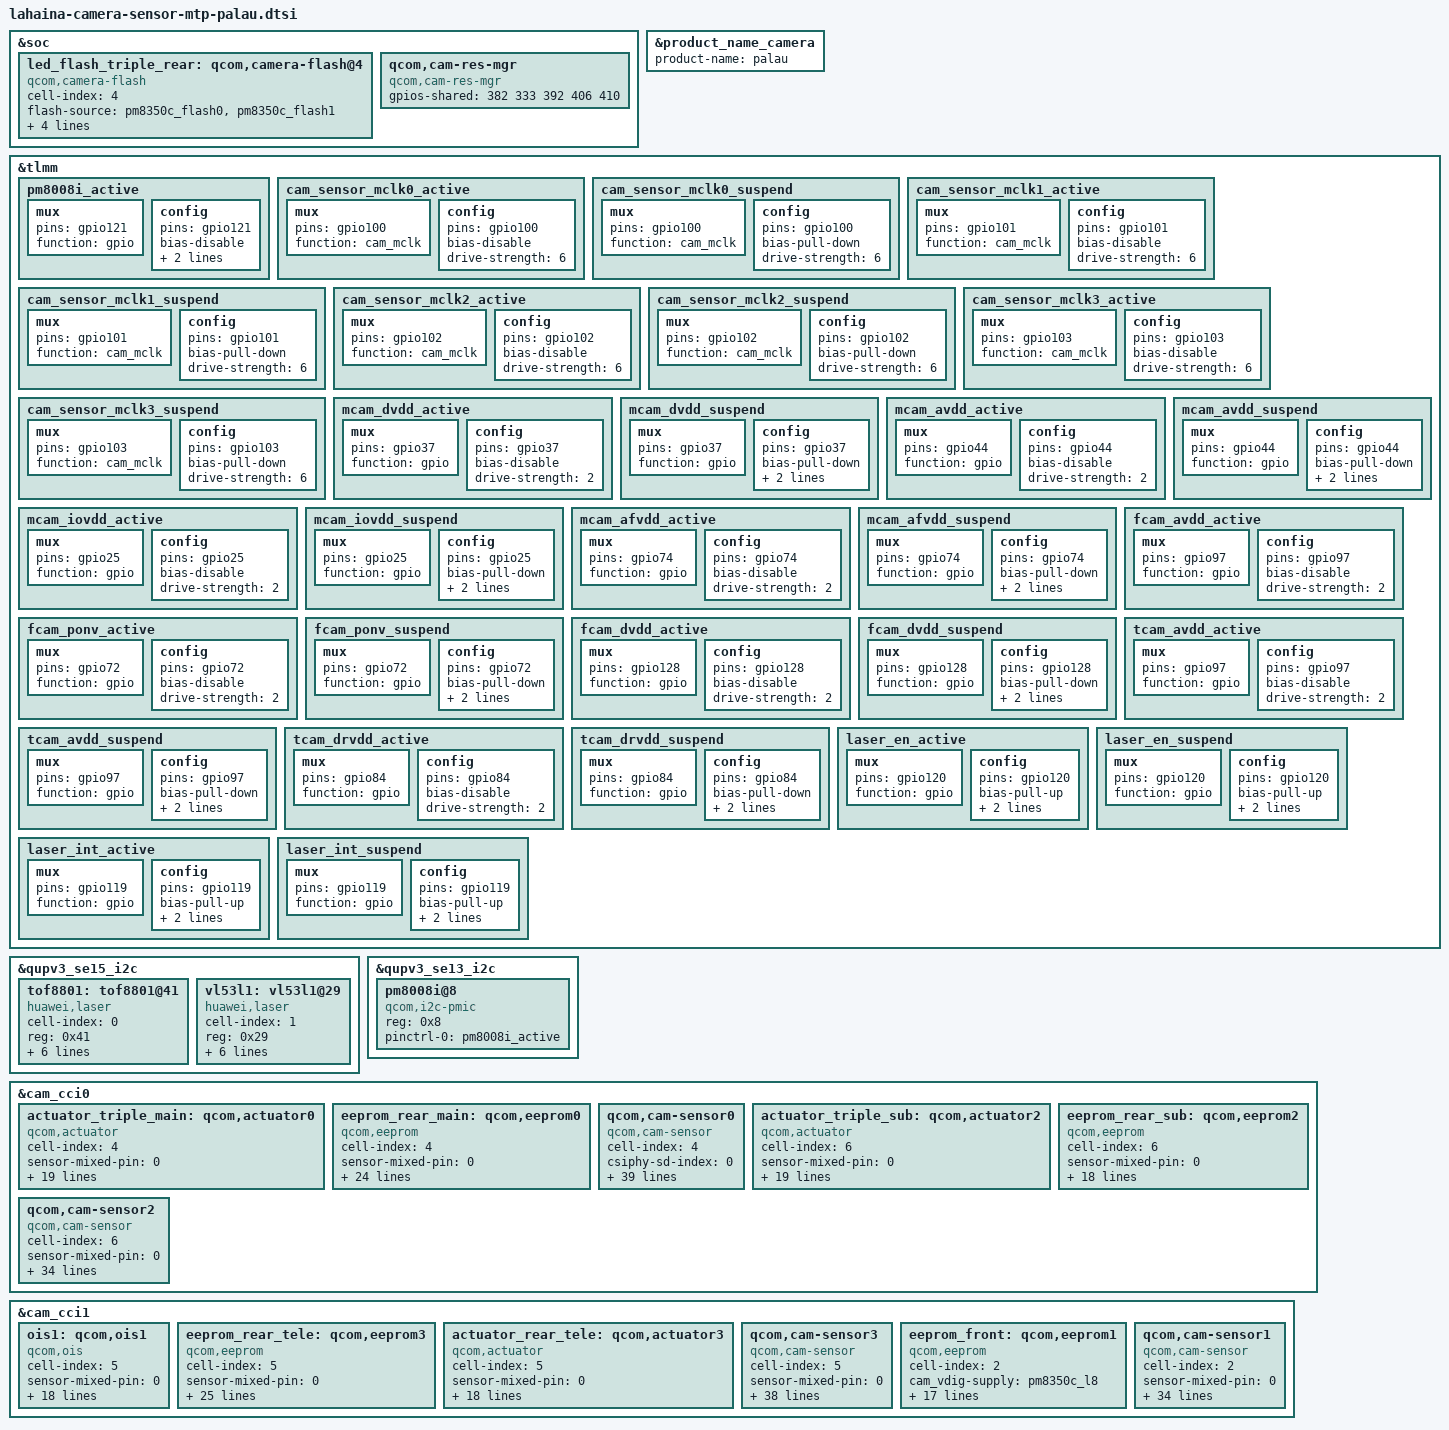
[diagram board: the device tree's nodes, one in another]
#include <dt-bindings/clock/qcom,camcc-lahaina.h>

&soc {
	led_flash_triple_rear: qcom,camera-flash@4 {
		cell-index = <4>;
		compatible = "qcom,camera-flash";
		flash-source = <&pm8350c_flash0 &pm8350c_flash1>;
		torch-source = <&pm8350c_torch0 &pm8350c_torch1>;
		switch-source = <&pm8350c_switch2>;
		torch-light-num = <0 1>;
		torch-light-name = "torch-light0", "torch-light1";
		status = "ok";
	};

	qcom,cam-res-mgr {
		compatible = "qcom,cam-res-mgr";
		status = "ok";
		gpios-shared = <382 333 392 406 410>;
	};
};

&product_name_camera {
    product-name = "palau";
};

&tlmm {
	pm8008i_active {
		mux {
			pins = "gpio121";
			function = "gpio";
		};

		config {
			pins = "gpio121";
			bias-disable;
			output-low;
			drive-strength = <2>;
		};
	};

	cam_sensor_mclk0_active: cam_sensor_mclk0_active {
		/* MCLK0 */
		mux {
			pins = "gpio100";
			function = "cam_mclk";
		};

		config {
			pins = "gpio100";
			bias-disable; /* No PULL */
			drive-strength = <6>; /* 6 MA */
		};
	};

	cam_sensor_mclk0_suspend: cam_sensor_mclk0_suspend {
		/* MCLK0 */
		mux {
			pins = "gpio100";
			function = "cam_mclk";
		};

		config {
			pins = "gpio100";
			bias-pull-down; /* PULL DOWN */
			drive-strength = <6>; /* 6 MA */
		};
	};

	cam_sensor_mclk1_active: cam_sensor_mclk1_active {
		/* MCLK1 */
		mux {
			pins = "gpio101";
			function = "cam_mclk";
		};

		config {
			pins = "gpio101";
			bias-disable; /* No PULL */
			drive-strength = <6>; /* 6 MA */
		};
	};

	cam_sensor_mclk1_suspend: cam_sensor_mclk1_suspend {
		/* MCLK1 */
		mux {
			pins = "gpio101";
			function = "cam_mclk";
		};

		config {
			pins = "gpio101";
			bias-pull-down; /* PULL DOWN */
			drive-strength = <6>; /* 6 MA */
		};
	};

	cam_sensor_mclk2_active: cam_sensor_mclk2_active {
		/* MCLK2 */
		mux {
			pins = "gpio102";
			function = "cam_mclk";
		};

		config {
			pins = "gpio102";
			bias-disable; /* No PULL */
			drive-strength = <6>; /* 6 MA */
		};
	};

	cam_sensor_mclk2_suspend: cam_sensor_mclk2_suspend {
		/* MCLK2 */
		mux {
			pins = "gpio102";
			function = "cam_mclk";
		};

		config {
			pins = "gpio102";
			bias-pull-down; /* PULL DOWN */
			drive-strength = <6>; /* 6 MA */
		};
	};

	cam_sensor_mclk3_active: cam_sensor_mclk3_active {
		/* MCLK3 */
		mux {
			pins = "gpio103";
			function = "cam_mclk";
		};

		config {
			pins = "gpio103";
			bias-disable; /* No PULL */
			drive-strength = <6>; /* 6 MA */
		};
	};

	cam_sensor_mclk3_suspend: cam_sensor_mclk3_suspend {
		/* MCLK3 */
		mux {
			pins = "gpio103";
			function = "cam_mclk";
		};

		config {
			pins = "gpio103";
			bias-pull-down; /* PULL DOWN */
			drive-strength = <6>; /* 6 MA */
		};
	};


	mcam_dvdd_active: mcam_dvdd_active {
		/* DVDD 0-for main */
		mux {
			pins = "gpio37";
			function = "gpio";
		};

		config {
			pins = "gpio37";
			bias-disable; /* No PULL */
			drive-strength = <2>; /* 2 MA */
		};
	};

	mcam_dvdd_suspend: mcam_dvdd_suspend {
		mux {
			pins = "gpio37";
			function = "gpio";
		};

		config {
			pins = "gpio37";
			bias-pull-down; /* PULL DOWN */
			drive-strength = <2>; /* 2 MA */
			output-low;
		};
	};

	mcam_avdd_active: mcam_avdd_active {
		mux {
			pins = "gpio44";
			function = "gpio";
		};

		config {
			pins = "gpio44";
			bias-disable; /* No PULL */
			drive-strength = <2>; /* 2 MA */
		};
	};

	mcam_avdd_suspend: mcam_avdd_suspend {
		mux {
			pins = "gpio44";
			function = "gpio";
		};

		config {
			pins = "gpio44";
			bias-pull-down; /* PULL DOWN */
			drive-strength = <2>; /* 2 MA */
			output-low;
		};
	};

	mcam_iovdd_active: mcam_iovdd_active {
		mux {
			pins = "gpio25";
			function = "gpio";
		};

		config {
			pins = "gpio25";
			bias-disable; /* No PULL */
			drive-strength = <2>; /* 2 MA */
		};
	};

	mcam_iovdd_suspend: mcam_iovdd_suspend {
		mux {
			pins = "gpio25";
			function = "gpio";
		};

		config {
			pins = "gpio25";
			bias-pull-down; /* PULL DOWN */
			drive-strength = <2>; /* 2 MA */
			output-low;
		};
	};

	mcam_afvdd_active: mcam_afvdd_active {
		mux {
			pins = "gpio74";
			function = "gpio";
		};

		config {
			pins = "gpio74";
			bias-disable; /* No PULL */
			drive-strength = <2>; /* 2 MA */
		};
	};

	mcam_afvdd_suspend: mcam_afvdd_suspend {
		mux {
			pins = "gpio74";
			function = "gpio";
		};

		config {
			pins = "gpio74";
			bias-pull-down; /* PULL DOWN */
			drive-strength = <2>; /* 2 MA */
			output-low;
		};
	};

	fcam_avdd_active: fcam_avdd_active {
		mux {
			pins = "gpio97";
			function = "gpio";
		};

		config {
			pins = "gpio97";
			bias-disable; /* No PULL */
			drive-strength = <2>; /* 2 MA */
		};
	};
	fcam_ponv_active: fcam_ponv_active {
		mux {
			pins = "gpio72";
			function = "gpio";
		};

		config {
			pins = "gpio72";
			bias-disable; /* No PULL */
			drive-strength = <2>; /* 2 MA */
		};
	};

	fcam_ponv_suspend: fcam_ponv_suspend {
		mux {
			pins = "gpio72";
			function = "gpio";
		};

		config {
			pins = "gpio72";
			bias-pull-down; /* PULL DOWN */
			drive-strength = <2>; /* 2 MA */
			output-low;
		};
	};

	fcam_dvdd_active: fcam_dvdd_active {
		mux {
			pins = "gpio128";
			function = "gpio";
		};

		config {
			pins = "gpio128";
			bias-disable; /* No PULL */
			drive-strength = <2>; /* 2 MA */
		};
	};

	fcam_dvdd_suspend: fcam_dvdd_suspend {
		mux {
			pins = "gpio128";
			function = "gpio";
		};

		config {
			pins = "gpio128";
			bias-pull-down; /* PULL DOWN */
			drive-strength = <2>; /* 2 MA */
			output-low;
		};
	};

	tcam_avdd_active: tcam_avdd_active {
		mux {
			pins = "gpio97";
			function = "gpio";
		};

		config {
			pins = "gpio97";
			bias-disable; /* No PULL */
			drive-strength = <2>; /* 2 MA */
		};
	};

	tcam_avdd_suspend: tcam_avdd_suspend {
		mux {
			pins = "gpio97";
			function = "gpio";
		};

		config {
			pins = "gpio97";
			bias-pull-down; /* PULL DOWN */
			drive-strength = <2>; /* 2 MA */
			output-low;
		};
	};

	tcam_drvdd_active: tcam_drvdd_active {
		mux {
			pins = "gpio84";
			function = "gpio";
		};

		config {
			pins = "gpio84";
			bias-disable; /* No PULL */
			drive-strength = <2>; /* 2 MA */
		};
	};

	tcam_drvdd_suspend: tcam_drvdd_suspend {
		mux {
			pins = "gpio84";
			function = "gpio";
		};

		config {
			pins = "gpio84";
			bias-pull-down; /* PULL DOWN */
			drive-strength = <2>; /* 2 MA */
			output-low;
		};
	};

	laser_en_active: laser_en_active {
		/* laser en pin */
		mux {
			pins = "gpio120";
			function = "gpio";
		};

		config {
			pins = "gpio120";
			bias-pull-up; /* PULL UP */
			drive-strength = <2>; /* 2 MA */
			input-enable;
		};
	};

	laser_en_suspend: laser_en_suspend {
		/* laser en pin */
		mux {
			pins = "gpio120";
			function = "gpio";
		};

		config {
			pins = "gpio120";
			bias-pull-up; /* PULL UP */
			drive-strength = <2>; /* 2 MA */
			input-enable;
		};
	};

	laser_int_active: laser_int_active {
		/* laser int pin */
		mux {
			pins = "gpio119";
			function = "gpio";
		};

		config {
			pins = "gpio119";
			bias-pull-up; /* PULL UP */
			drive-strength = <2>; /* 2 MA */
			input-enable;
		};
	};

	laser_int_suspend: laser_int_suspend {
		/* laser int pin */
		mux {
			pins = "gpio119";
			function = "gpio";
		};

		config {
			pins = "gpio119";
			bias-pull-up; /* PULL UP */
			drive-strength = <2>; /* 2 MA */
			input-enable;
		};
	};
};

/* laser */
&qupv3_se15_i2c {
	status = "ok";

	tof8801: tof8801@41 {
		cell-index = <0>;
		compatible = "huawei,laser";
		reg = <0x41>;
		gpios = <&tlmm 120 0>,
			<&tlmm 119 0>;
		pinctrl-names = "laser_int_active", "laser_en_active";
		pinctrl-0 = <&laser_int_active>;
		pinctrl-1 = <&laser_en_active>;
		gpio-req-tbl-num = <0>;
		gpio-req-tbl-flags = <0>;
		gpio-req-tbl-label = "CAM_VAF0";
		status = "ok";
	};
	vl53l1: vl53l1@29 {
		cell-index = <1>;
		compatible = "huawei,laser";
		reg = <0x29>;
		gpios = <&tlmm 120 0>,
			<&tlmm 119 0>;
		pinctrl-names = "laser_int_active", "laser_en_active";
		pinctrl-0 = <&laser_int_active>;
		pinctrl-1 = <&laser_en_active>;
		gpio-req-tbl-num = <0>;
		gpio-req-tbl-flags = <0>;
		gpio-req-tbl-label = "CAM_VAF0";
		status = "ok";
	};

};
&qupv3_se13_i2c {
	#address-cells = <1>;
	#size-cells = <0>;
	status = "ok";

	pm8008i@8 {
		compatible = "qcom,i2c-pmic";
		reg = <0x8>;
		#address-cells = <1>;
		#size-cells = <0>;

		pinctrl-names = "default";
		pinctrl-0 = <&pm8008i_active>;

	};
};

&cam_cci0 {
	actuator_triple_main: qcom,actuator0 {
		cell-index = <4>;
		compatible = "qcom,actuator";
		sensor-mixed-pin = <0>;
		cam_clk-supply = <&cam_cc_titan_top_gdsc>;
		regulator-names = "cam_clk";
		rgltr-cntrl-support;
		rgltr-min-voltage = <0>;
		rgltr-max-voltage = <0>;
		rgltr-load-current = <0>;
		gpio-no-mux = <0>;
		gpios = <&tlmm 74 0>,
			<&tlmm 25 0>, /* iovdd */
			<&tlmm 98 0>;
		gpio-mixed1 = <0>;
		gpio-mixed2 = <1>;
		gpio-custom1 = <2>;
		gpio-req-tbl-num = <0 1 2>;
		gpio-req-tbl-flags = <0 0 0>;
		gpio-req-tbl-label = "CAM_MIXED1",
					"CAM_MIXED2",
					"CAM_CUSTOM1";
		cci-master = <1>;
		status = "ok";
		clocks = <&clock_camcc CAM_CC_MCLK0_CLK>;
		clock-names = "cam_clk";
		clock-cntl-level = "nominal";
		clock-rates = <19200000>;
	};
	eeprom_rear_main: qcom,eeprom0 {
		cell-index = <4>;
		compatible = "qcom,eeprom";
		sensor-mixed-pin = <0>;
		cam_clk-supply = <&cam_cc_titan_top_gdsc>;
		regulator-names = "cam_clk";
		rgltr-cntrl-support;
		rgltr-min-voltage = <0>;
		rgltr-max-voltage = <0>;
		rgltr-load-current = <0>;
		gpio-no-mux = <0>;
		gpios = <&tlmm 100 0>, /* mclk */
			<&tlmm 16 0>, /* rst1 */
			<&tlmm 98 0>, /* boost_en */
			<&tlmm 44 0>, /* avdd */
			<&tlmm 37 0>, /* dvdd */
			<&tlmm 25 0>, /* iovdd */
			<&tlmm 74 0>; /* afvdd */
		gpio-reset = <1>;
		gpio-custom1 = <2>;
		gpio-mixed3 = <3>;
		gpio-mixed2 = <4>;
		gpio-mixed1 = <5>;
		gpio-mixed4 = <6>;
		gpio-req-tbl-num = <0 1 2 3 4 5 6>;
		gpio-req-tbl-flags = <1 0 0 0 0 0 0>;
		gpio-req-tbl-label = "CAMIF_MCLK0",
					"CAM_RESET0",
					"CAM_CUSTOM1",
					"CAM_MIXED3",
					"CAM_MIXED2",
					"CAM_MIXED1",
					"CAM_MIXED4";
		cci-master = <1>;
		status = "ok";
		clocks = <&clock_camcc CAM_CC_MCLK0_CLK>;
		clock-names = "cam_clk";
		clock-cntl-level = "nominal";
		clock-rates = <19200000>;
	};
	qcom,cam-sensor0 {
		cell-index = <4>;
		compatible = "qcom,cam-sensor";
		csiphy-sd-index = <0>;
		sensor-mixed-pin = <0>;
		sensor-position-roll = <90>;
		sensor-position-pitch = <0>;
		sensor-position-yaw = <180>;
		eeprom-src = <&eeprom_rear_main>;
		actuator-src = <&actuator_triple_main>;
		led-flash-src = <&led_flash_triple_rear>;
		cam_clk-supply = <&cam_cc_titan_top_gdsc>;
		regulator-names = "cam_clk";
		rgltr-cntrl-support;
		rgltr-min-voltage = <0>;
		rgltr-max-voltage = <0>;
		rgltr-load-current = <0>;
		gpio-no-mux = <0>;
		pinctrl-names = "cam_default", "cam_suspend";
		pinctrl-0 = <&cam_sensor_mclk0_active
				&mcam_dvdd_active
				&mcam_avdd_active
				&mcam_iovdd_active
				&mcam_afvdd_active
				&cam_sensor_active_rst1>;
		pinctrl-1 = <&cam_sensor_mclk0_suspend
				&mcam_dvdd_suspend
				&mcam_avdd_suspend
				&mcam_iovdd_suspend
				&mcam_afvdd_suspend
				&cam_sensor_suspend_rst1>;
		gpios = <&tlmm 100 0>, /* mclk */
			<&tlmm 16 0>, /* rst1 */
			<&tlmm 98 0>, /* boost_en */
			<&tlmm 44 0>, /* avdd */
			<&tlmm 37 0>, /* dvdd */
			<&tlmm 25 0>, /* iovdd */
			<&tlmm 74 0>; /* afvdd */
		gpio-reset = <1>;
		gpio-custom1 = <2>;
		gpio-mixed1 = <3>;
		gpio-mixed2 = <4>;
		gpio-mixed3 = <5>;
		gpio-mixed4 = <6>;
		gpio-req-tbl-num = <0 1 2 3 4 5 6>;
		gpio-req-tbl-flags = <1 0 0 0 0 0 0>;
		gpio-req-tbl-label = "CAMIF_MCLK0",
					"CAM_RESET0",
					"CAM_CUSTOM1",
					"CAM_MIXED1",
					"CAM_MIXED2",
					"CAM_MIXED3",
					"CAM_MIXED4";
		cci-master = <1>;
		status = "ok";
		clocks = <&clock_camcc CAM_CC_MCLK0_CLK>;
		clock-names = "cam_clk";
		clock-cntl-level = "nominal";
		clock-rates = <19200000>;
	};

	actuator_triple_sub: qcom,actuator2 {
		cell-index = <6>;
		compatible = "qcom,actuator";
		sensor-mixed-pin = <0>;
		cam_clk-supply = <&cam_cc_titan_top_gdsc>;
		regulator-names = "cam_clk";
		rgltr-cntrl-support;
		rgltr-min-voltage = <0>;
		rgltr-max-voltage = <0>;
		rgltr-load-current = <0>;
		gpio-no-mux = <0>;
		gpios = <&tlmm 74 0>,
			<&tlmm 25 0>, /* iovdd */
			<&tlmm 98 0>;
		gpio-mixed1 = <0>;
		gpio-mixed2 = <1>;
		gpio-custom1 = <2>;
		gpio-req-tbl-num = <0 1 2>;
		gpio-req-tbl-flags = <0 0 0>;
		gpio-req-tbl-label = "CAM_MIXED1",
					"CAM_MIXED2",
					"CAM_CUSTOM1";
		cci-master = <0>;
		status = "ok";
		clocks = <&clock_camcc CAM_CC_MCLK1_CLK>;
		clock-names = "cam_clk";
		clock-cntl-level = "nominal";
		clock-rates = <19200000>;
	};

	eeprom_rear_sub: qcom,eeprom2 {
		cell-index = <6>;
		compatible = "qcom,eeprom";
		sensor-mixed-pin = <0>;
		cam_clk-supply = <&cam_cc_titan_top_gdsc>;
		regulator-names = "cam_clk";
		rgltr-cntrl-support;
		rgltr-min-voltage = <0>;
		rgltr-max-voltage = <0>;
		rgltr-load-current = <0>;
		gpio-no-mux = <0>;
		gpios = <&tlmm 101 0>,
			<&tlmm 98 0>,
			<&tlmm 25 0>;
		gpio-custom1 = <1>;
		gpio-mixed1 = <2>;
		gpio-req-tbl-num = <0 1 2>;
		gpio-req-tbl-flags = <1 0 0>;
		gpio-req-tbl-label = "CAMIF_MCLK1",
					"CAM_SUB_CUSTOM1",
					"CAM_MIXED1";
		cci-master = <0>;
		status = "ok";
		clocks = <&clock_camcc CAM_CC_MCLK1_CLK>;
		clock-names = "cam_clk";
		clock-cntl-level = "nominal";
		clock-rates = <19200000>;
	};
	qcom,cam-sensor2 {
		cell-index = <6>;
		compatible = "qcom,cam-sensor";
		sensor-mixed-pin = <0>;
		csiphy-sd-index = <2>;
		sensor-position-roll = <90>;
		sensor-position-pitch = <0>;
		sensor-position-yaw = <180>;
		actuator-src = <&actuator_triple_sub>;
		eeprom-src = <&eeprom_rear_sub>;
		cam_clk-supply = <&cam_cc_titan_top_gdsc>;
		regulator-names = "cam_clk";
		rgltr-cntrl-support;
		rgltr-min-voltage = <0>;
		rgltr-max-voltage = <0>;
		rgltr-load-current = <0>;
		gpio-no-mux = <0>;
		pinctrl-names = "cam_default", "cam_suspend";
		pinctrl-0 = <&cam_sensor_mclk1_active
				&cam_sensor_active_rst2>;
		pinctrl-1 = <&cam_sensor_mclk1_suspend
				&cam_sensor_suspend_rst2>;
		gpios = <&tlmm 101 0>,
			<&tlmm 106 0>,
			<&tlmm 98 0>,
			<&tlmm 44 0>,
			<&tlmm 37 0>,
			<&tlmm 74 0>,
			<&tlmm 25 0>;
		gpio-reset = <1>;
		gpio-custom1 = <2>;
		gpio-mixed1 = <3>;
		gpio-mixed2 = <4>;
		gpio-mixed3 = <5>;
		gpio-mixed4 = <6>;
		gpio-req-tbl-num = <0 1 2 3 4 5 6>;
		gpio-req-tbl-flags = <1 0 0 0 0 0 0>;
		gpio-req-tbl-label = "CAMIF_MCLK1",
					"CAM_RESET2",
					"CAM_SUB_CUSTOM1",
					"CAM_MIXED1",
					"CAM_MIXED2",
					"CAM_MIXED3",
					"CAM_MIXED4";
		cci-master = <0>;
		status = "ok";
		clocks = <&clock_camcc CAM_CC_MCLK1_CLK>;
		clock-names = "cam_clk";
		clock-cntl-level = "nominal";
		clock-rates = <19200000>;
	};
};
&cam_cci1 {
	ois1: qcom,ois1 {
		cell-index = <5>;
		compatible = "qcom,ois";
		sensor-mixed-pin = <0>;
		cam_clk-supply = <&cam_cc_titan_top_gdsc>;
		regulator-names = "cam_clk";
		rgltr-cntrl-support;
		rgltr-min-voltage = <0>;
		rgltr-max-voltage = <0>;
		rgltr-load-current = <0>;
		gpio-no-mux = <0>;
		gpios = <&tlmm 102 0>, /* mclk */
			<&tlmm 74 0>,
			<&tlmm 84 0>; /* drvdd */
		gpio-mixed1 = <1>;
		gpio-custom2 = <2>;
		gpio-req-tbl-num = <0 1 2>;
		gpio-req-tbl-flags = <1 0 0>;
		gpio-req-tbl-label = "CAMIF_MCLK2",
					"CAM_MIXED1",
					"CAM_TELE_CUSTOM2";
		cci-master = <0>;
		status = "ok";
		clocks = <&clock_camcc CAM_CC_MCLK2_CLK>;
		clock-names = "cam_clk";
		clock-cntl-level = "nominal";
		clock-rates = <19200000>;
	};
	eeprom_rear_tele: qcom,eeprom3 {
		cell-index = <5>;
		compatible = "qcom,eeprom";
		sensor-mixed-pin = <0>;
		cam_clk-supply = <&cam_cc_titan_top_gdsc>;
		regulator-names = "cam_clk";
		rgltr-cntrl-support;
		rgltr-min-voltage = <0>;
		rgltr-max-voltage = <0>;
		rgltr-load-current = <0>;
		gpio-no-mux = <0>;
		gpios = <&tlmm 102 0>, /* mclk */
			<&tlmm 117 0>, /* rst1 */
			<&tlmm 98 0>, /* boost_en */
			<&tlmm 25 0>, /* iovdd */
			<&tlmm 97 0>, /* avdd */
			<&tlmm 37 0>, /* dvdd */
			<&tlmm 74 0>, /* afvdd */
			<&tlmm 84 0>; /* drvdd */
		gpio-reset = <1>;
		gpio-custom1 = <2>;
		gpio-mixed1 = <3>;
		gpio-mixed2 = <4>;
		gpio-mixed3 = <5>;
		gpio-mixed4 = <6>;
		gpio-custom2 = <7>;
		gpio-req-tbl-num = <0 1 2 3 4 5 6 7>;
		gpio-req-tbl-flags = <1 0 0 0 0 0 0 0>;
		gpio-req-tbl-label = "CAMIF_MCLK2",
					"CAM_RESET3",
					"CAM_TELE_CUSTOM1",
					"CAM_MIXED1",
					"CAM_MIXED2",
					"CAM_MIXED3",
					"CAM_MIXED4",
					"CAM_TELE_CUSTOM2";
		cci-master = <0>;
		status = "ok";
		clocks = <&clock_camcc CAM_CC_MCLK2_CLK>;
		clock-names = "cam_clk";
		clock-cntl-level = "nominal";
		clock-rates = <19200000>;
	};
	actuator_rear_tele: qcom,actuator3 {
		cell-index = <5>;
		compatible = "qcom,actuator";
		sensor-mixed-pin = <0>;
		cam_clk-supply = <&cam_cc_titan_top_gdsc>;
		regulator-names = "cam_clk";
		rgltr-cntrl-support;
		rgltr-min-voltage = <0>;
		rgltr-max-voltage = <0>;
		rgltr-load-current = <0>;
		gpio-no-mux = <0>;
		gpios = <&tlmm 102 0>, /* mclk */
			<&tlmm 74 0>,
			<&tlmm 84 0>; /* iovdd */
		gpio-mixed1 = <1>;
		gpio-custom2 = <2>;
		gpio-req-tbl-num = <0 1 2>;
		gpio-req-tbl-flags = <1 0 0>;
		gpio-req-tbl-label = "CAMIF_MCLK2",
					"CAM_MIXED1",
					"CAM_TELE_CUSTOM2";
		cci-master = <0>;
		status = "ok";
		clocks = <&clock_camcc CAM_CC_MCLK2_CLK>;
		clock-names = "cam_clk";
		clock-cntl-level = "nominal";
		clock-rates = <19200000>;
	};
	qcom,cam-sensor3 { /* tele */
		cell-index = <5>;
		compatible = "qcom,cam-sensor";
		sensor-mixed-pin = <0>;
		csiphy-sd-index = <1>;
		sensor-position-roll = <90>;
		sensor-position-pitch = <0>;
		sensor-position-yaw = <180>;
		ois-src  = <&ois1>;
		eeprom-src = <&eeprom_rear_tele>;
		actuator-src = <&actuator_rear_tele>;
		cam_clk-supply = <&cam_cc_titan_top_gdsc>;
		regulator-names = "cam_clk";
		rgltr-cntrl-support;
		rgltr-min-voltage = <0>;
		rgltr-max-voltage = <0>;
		rgltr-load-current = <0>;
		gpio-no-mux = <0>;
		pinctrl-names = "cam_default", "cam_suspend";
		pinctrl-0 = <&cam_sensor_mclk2_active
				&tcam_avdd_active
				&tcam_drvdd_active
				&cam_sensor_active_rst3>;
		pinctrl-1 = <&cam_sensor_mclk2_suspend
				&tcam_avdd_suspend
				&tcam_drvdd_suspend
				&cam_sensor_suspend_rst3>;
		gpios = <&tlmm 102 0>, /* mclk */
			<&tlmm 117 0>, /* rst */
			<&tlmm 98 0>, /* boost_en */
			<&tlmm 25 0>, /* iovdd */
			<&tlmm 97 0>, /* avdd */
			<&tlmm 37 0>, /* dvdd */
			<&tlmm 74 0>, /* afvdd */
			<&tlmm 84 0>; /* drvdd */
		gpio-reset = <1>;
		gpio-custom1 = <2>;
		gpio-mixed1 = <3>;
		gpio-mixed2 = <4>;
		gpio-mixed3 = <5>;
		gpio-mixed4 = <6>;
		gpio-custom2 = <7>;
		gpio-req-tbl-num = <0 1 2 3 4 5 6 7>;
		gpio-req-tbl-flags = <1 0 0 0 0 0 0 0>;
		gpio-req-tbl-label = "CAMIF_MCLK2",
					"CAM_RESET3",
					"CAM_TELE_CUSTOM1",
					"CAM_MIXED1",
					"CAM_MIXED2",
					"CAM_MIXED3",
					"CAM_MIXED4",
					"CAM_TELE_CUSTOM2";
		cci-master = <0>;
		status = "ok";
		clocks = <&clock_camcc CAM_CC_MCLK2_CLK>;
		clock-names = "cam_clk";
		clock-cntl-level = "nominal";
		clock-rates = <19200000>;
	};

	eeprom_front: qcom,eeprom1 {
		cell-index = <2>;
		compatible = "qcom,eeprom";
		cam_vdig-supply = <&pm8350c_l8>;
		cam_clk-supply = <&cam_cc_titan_top_gdsc>;
		regulator-names = "cam_vio", "cam_clk";
		rgltr-cntrl-support;
		rgltr-min-voltage = <1750000 0>;
		rgltr-max-voltage = <1850000 0>;
		rgltr-load-current = <10000 0>; /* how to configure */
		gpio-no-mux = <0>;
		gpios = <&tlmm 103 0>, /* mclk */
			<&tlmm 98 0>; /* boost_en */
		gpio-custom1 = <1>;
		gpio-req-tbl-num = <0 1>;
		gpio-req-tbl-flags = <1 0>;
		gpio-req-tbl-label = "CAMIF_MCLK3",
					"CAM_FONT_CUSTOM1";
		cci-master = <1>;
		status = "ok";
		clocks = <&clock_camcc CAM_CC_MCLK3_CLK>;
		clock-names = "cam_clk";
		clock-cntl-level = "nominal";
		clock-rates = <19200000>;
	};
	qcom,cam-sensor1 { /* front */
		cell-index = <2>;
		compatible = "qcom,cam-sensor";
		sensor-mixed-pin = <0>;
		csiphy-sd-index = <3>;
		sensor-position-roll = <270>;
		sensor-position-pitch = <0>;
		sensor-position-yaw = <0>;
		eeprom-src = <&eeprom_front>;
		cam_vdig-supply = <&pm8350c_l8>;
		cam_clk-supply = <&cam_cc_titan_top_gdsc>;
		regulator-names = "cam_vio", "cam_clk";
		rgltr-cntrl-support;
		rgltr-min-voltage = <1750000 0>;
		rgltr-max-voltage = <1850000 0>;
		rgltr-load-current = <10000 0>; /* how to configure */
		gpio-no-mux = <0>;
		pinctrl-names = "cam_default", "cam_suspend";
		pinctrl-0 = <&cam_sensor_mclk3_active
				&fcam_ponv_active

				&cam_sensor_active_rst0>;
		pinctrl-1 = <&cam_sensor_mclk3_suspend
				&fcam_ponv_suspend

				&cam_sensor_suspend_rst0>;
		gpios = <&tlmm 103 0>, /* mclk */
			<&tlmm 17 0>, /* rst */
			<&tlmm 98 0>, /* boost_en */
			<&tlmm 44 0>, /* avdd */
			<&tlmm 97 0>, /* avdd1 */
			<&tlmm 128 0>, /* dvdd */
			<&tlmm 72 0>;  /* ponv */
		gpio-reset = <1>;
		gpio-custom1 = <2>;
		gpio-mixed1 = <3>;
		gpio-mixed2 = <4>;
		gpio-mixed3 = <5>;
		gpio-custom2 = <6>;
		gpio-req-tbl-num = <0 1 2 3 4 5 6>;
		gpio-req-tbl-flags = <1 0 0 0 0 0 0>;
		gpio-req-tbl-label = "CAMIF_MCLK3",
					"CAM_RESET1",
					"CAM_FONT_CUSTOM1",
					"CAM_mixed1",
					"CAM_mixed2",
					"CAM_mixed3",
					"CAM_FONT_CUSTOM2";
		cci-master = <1>;
		status = "ok";
		clocks = <&clock_camcc CAM_CC_MCLK3_CLK>;
		clock-names = "cam_clk";
		clock-cntl-level = "nominal";
		clock-rates = <19200000>;
	};
};
